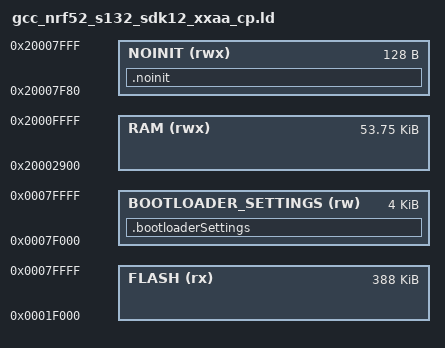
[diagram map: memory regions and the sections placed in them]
OUTPUT_FORMAT ("elf32-littlearm", "elf32-bigarm", "elf32-littlearm")
SEARCH_DIR(.)
SEARCH_DIR("../../../../src")
SEARCH_DIR("../../../../../src")
SEARCH_DIR("../../../../../../src")
SEARCH_DIR("../../../../../EHAL/ARM/src")
GROUP(-lgcc -lc -lnosys -lCMSIS)

MEMORY
{
	FLASH (rx) : ORIGIN = 0x1f000, LENGTH = 0x61000
	RAM (rwx) :  ORIGIN = 0x20002900, LENGTH = 0xd700
	/** Location of non initialized RAM. Non initialized RAM is used for exchanging bond information
	*  from application to bootloader when using buttonluss DFU OTA.
	*/
	NOINIT (rwx) :  ORIGIN = 0x20007F80, LENGTH = 0x80

	/** Location of bootloader setting in flash. */
	BOOTLOADER_SETTINGS (rw) : ORIGIN = 0x0007F000, LENGTH = 0x1000
}


SECTIONS
{
	/* Place the bootloader settings page in flash. */
	.bootloaderSettings(NOLOAD) :
	{

	} > BOOTLOADER_SETTINGS

	/* No init RAM section in bootloader. Used for bond information exchange. */
	.noinit(NOLOAD) :
	{

	} > NOINIT
}

SECTIONS
{
  .pwr_mgmt_data :
  {
    PROVIDE(__start_pwr_mgmt_data = .);
    KEEP(*(.pwr_mgmt_data))
    PROVIDE(__stop_pwr_mgmt_data = .);
  } > FLASH
} INSERT AFTER .text

SECTIONS
{
	.fs_data :
	{
		PROVIDE(__start_fs_data = .);
		KEEP(*(.fs_data))
		PROVIDE(__stop_fs_data = .);
	} > RAM AT > FLASH
} INSERT AFTER .data;

INCLUDE "gcc_arm_flash.ld"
